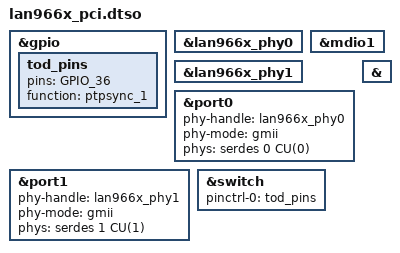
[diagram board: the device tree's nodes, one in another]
// SPDX-License-Identifier: GPL-2.0
/*
 * Copyright (C) 2022 Microchip UNG
 */

#include <dt-bindings/gpio/gpio.h>
#include <dt-bindings/phy/phy-lan966x-serdes.h>

/dts-v1/;
/plugin/;

/ {
	fragment@0 {
		target-path = "";

		/*
		 * These properties allow to avoid a dtc warnings.
		 * The real interrupt controller is the PCI device itself. It
		 * is the node on which the device tree overlay will be applied.
		 * This node has those properties.
		 */
		#interrupt-cells = <1>;
		interrupt-controller;

		__overlay__ {
			#address-cells = <3>;
			#size-cells = <2>;

			#include "lan966x_pci.dtsi"
		};
	};
};

&gpio {
	tod_pins: tod_pins {
		pins = "GPIO_36";
		function = "ptpsync_1";
	};
};

&lan966x_phy0 {
	status = "okay";
};

&lan966x_phy1 {
	status = "okay";
};

&mdio1 {
	status = "okay";
};

&port0 {
	phy-handle = <&lan966x_phy0>;
	phy-mode = "gmii";
	phys = <&serdes 0 CU(0)>;
	status = "okay";
};

&port1 {
	phy-handle = <&lan966x_phy1>;
	phy-mode = "gmii";
	phys = <&serdes 1 CU(1)>;
	status = "okay";
};

&switch {
	pinctrl-names = "default";
	pinctrl-0 = <&tod_pins>;
	status = "okay";
};
